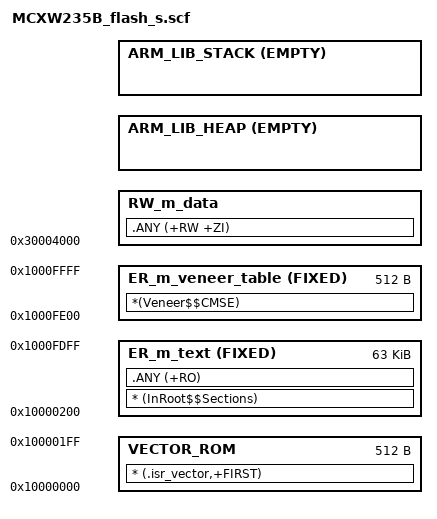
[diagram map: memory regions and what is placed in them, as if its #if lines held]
#!armclang --target=arm-arm-none-eabi -march=armv8-m.main -E -x c
/*
** ###################################################################
**     Processors:          MCXW235BIHNAR
**                          MCXW235BIUKAR
**
**     Compiler:            Keil ARM C/C++ Compiler
**
**
**     Copyright 2016 Freescale Semiconductor, Inc.
**     Copyright 2016-2024 NXP
**     SPDX-License-Identifier: BSD-3-Clause
**
**     http:                 www.nxp.com
**     mail:                 support@nxp.com
**
** ###################################################################
*/


/* Sizes */
#if (defined(__stack_size__))
  #define Stack_Size                   __stack_size__
#else
  #define Stack_Size                   0x0500
#endif

#if (defined(__heap_size__))
  #define Heap_Size                    __heap_size__
#else
  #define Heap_Size                    0x0400
#endif
/* The first 128kB of FLASH are used as secure memory. The rest of FLASH memory is non-secure memory. */
#define  m_interrupts_start            0x10000000
#define  m_interrupts_size             0x00000200

#define m_text_start                   0x10000200
#define m_text_size                    0x0000FC00

/* 112k (SRAM0 = 16k, SRAM1 = 32k, SRAM2 = 64K) RAM to fit data segment */
/* The first 32kB of data RAM is used as secure memory. The rest of data RAM memory is non-secure memory. */
#define  m_data_start                  0x30004000
#define  m_data_size                   0x00008000

/* 512B - memory for veneer table (NSC - secure, non-secure callable memory) */
#define  m_veneer_table_start          0x1000FE00
#define  m_veneer_table_size           0x200

#define  m_sramx_start                 0x14000000
#define  m_sramx_size                  0x10004000

LR_m_text m_interrupts_start m_interrupts_size+m_text_size+m_veneer_table_size {   ; load region size_region

  VECTOR_ROM m_interrupts_start m_interrupts_size { ; load address = execution address
    * (.isr_vector,+FIRST)
  }

  ER_m_text m_text_start FIXED m_text_size { ; load address = execution address
    * (InRoot$$Sections)
    .ANY (+RO)
  }

  RW_m_data m_data_start m_data_size-Stack_Size-Heap_Size { ; RW data
    .ANY (+RW +ZI)
  }
  ARM_LIB_HEAP +0 EMPTY Heap_Size {    ; Heap region growing up
  }
  ARM_LIB_STACK m_data_start+m_data_size EMPTY -Stack_Size { ; Stack region growing down
  }

  ER_m_veneer_table m_veneer_table_start FIXED m_veneer_table_size {; veneer table
    *(Veneer$$CMSE)
  }
}
